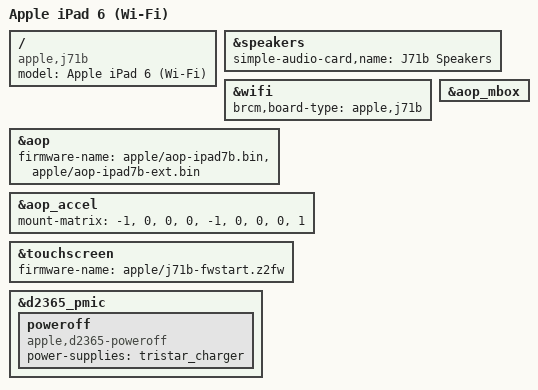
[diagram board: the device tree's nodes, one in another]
// SPDX-License-Identifier: GPL-2.0+ OR MIT
/*
 * Apple iPad 6 (Wi-Fi), J71b, iPad7,5 (A1893)
 * Copyright (c) 2022, Konrad Dybcio <konradybcio@kernel.org>
 */

/dts-v1/;

#include "t8010-ipad6.dtsi"

/ {
	compatible = "apple,j71b", "apple,t8010", "apple,arm-platform";
	model = "Apple iPad 6 (Wi-Fi)";
};

&speakers {
	simple-audio-card,name = "J71b Speakers";
};

&wifi {
	brcm,board-type = "apple,j71b";
};

&aop {
	firmware-name = "apple/aop-ipad7b.bin", "apple/aop-ipad7b-ext.bin";
	status = "okay";
};

&aop_mbox {
	status = "okay";
};

/*
 * The AOP reports the accelerometer in the device frame with y up when the
 * iPad is upright; desktops (iio-sensor-proxy) take upright as y down and
 * left/right accordingly, with z unchanged.
 */
&aop_accel {
	mount-matrix = "-1", "0", "0",
		       "0", "-1", "0",
		       "0", "0", "1";
};

&touchscreen {
	firmware-name = "apple/j71b-fwstart.z2fw";
};

&d2365_pmic {
	poweroff {
		compatible = "apple,d2365-poweroff";
		power-supplies = <&tristar_charger>;
	};
};
